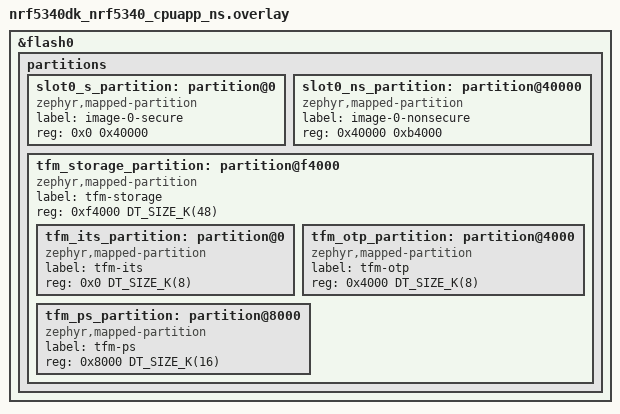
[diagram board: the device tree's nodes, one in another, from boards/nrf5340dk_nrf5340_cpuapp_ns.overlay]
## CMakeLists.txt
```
#
# Copyright (c) 2024 Nordic Semiconductor ASA
#
# SPDX-License-Identifier: LicenseRef-Nordic-5-Clause
#

cmake_minimum_required(VERSION 3.20.0)

find_package(Zephyr REQUIRED HINTS $ENV{ZEPHYR_BASE})
project(decompression_arm_thumb)

target_sources(app PRIVATE src/main.c)

generate_inc_file_for_target(
  app
  ${ZEPHYR_NRFXLIB_MODULE_DIR}/tests/subsys/nrf_compress/decompression/arm_thumb.dat
  ${ZEPHYR_BINARY_DIR}/include/generated/arm_thumb.inc
  )

generate_inc_file_for_target(
  app
  ${ZEPHYR_NRFXLIB_MODULE_DIR}/tests/subsys/nrf_compress/decompression/arm_thumb_compressed.dat
  ${ZEPHYR_BINARY_DIR}/include/generated/arm_thumb_compressed.inc
  )
```

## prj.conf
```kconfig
#
# Copyright (c) 2024 Nordic Semiconductor ASA
#
# SPDX-License-Identifier: LicenseRef-Nordic-5-Clause
#

CONFIG_ZTEST=y
CONFIG_ZTEST_STACK_SIZE=3086
CONFIG_NRF_COMPRESS=y
CONFIG_NRF_COMPRESS_DECOMPRESSION=y
CONFIG_NRF_COMPRESS_ARM_THUMB=y
CONFIG_LOG=y
```

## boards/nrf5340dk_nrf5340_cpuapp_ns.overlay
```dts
/delete-node/ &boot_partition;
/delete-node/ &slot0_partition;
/delete-node/ &slot1_partition;
/delete-node/ &tfm_ps_partition;
/delete-node/ &tfm_its_partition;
/delete-node/ &tfm_otp_partition;
/delete-node/ &storage_partition;

&flash0 {
	partitions {
		slot0_s_partition: partition@0 {
			compatible = "zephyr,mapped-partition";
			label = "image-0-secure";
			reg = <0x0 0x40000>;
		};

		slot0_ns_partition: partition@40000 {
			compatible = "zephyr,mapped-partition";
			label = "image-0-nonsecure";
			reg = <0x40000 0xb4000>;
		};

		tfm_storage_partition: partition@f4000 {
			compatible = "zephyr,mapped-partition";
			label = "tfm-storage";
			reg = <0xf4000 DT_SIZE_K(48)>;
			ranges = <0x0 0xf4000 DT_SIZE_K(48)>;
			#address-cells = <1>;
			#size-cells = <1>;

			tfm_its_partition: partition@0 {
				compatible = "zephyr,mapped-partition";
				label = "tfm-its";
				reg = <0x0 DT_SIZE_K(8)>;
			};

			tfm_otp_partition: partition@4000 {
				compatible = "zephyr,mapped-partition";
				label = "tfm-otp";
				reg = <0x4000 DT_SIZE_K(8)>;
			};

			tfm_ps_partition: partition@8000 {
				compatible = "zephyr,mapped-partition";
				label = "tfm-ps";
				reg = <0x8000 DT_SIZE_K(16)>;
			};
		};
	};
};
```

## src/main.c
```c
/*
 * Copyright (c) 2024 Nordic Semiconductor ASA
 *
 * SPDX-License-Identifier: LicenseRef-Nordic-5-Clause
 */

#include <zephyr/ztest.h>
#include <zephyr/kernel.h>
#include <nrf_compress/implementation.h>

/* Input valid ARM thumb filter compressed data */
static const uint8_t input_compressed[] = {
#include "arm_thumb_compressed.inc"
};

/* Output expected data */
static const uint8_t output_expected[] = {
#include "arm_thumb.inc"
};

#define PLUS_MINUS_OUTPUT_SIZE 2

ZTEST(nrf_compress_decompression, test_valid_implementation)
{
	int rc;
	uint32_t pos = 0;
	uint32_t offset;
	uint8_t *output;
	uint32_t output_size;
	uint32_t total_output_size = 0;
	struct nrf_compress_implementation *implementation = NULL;

	implementation = nrf_compress_implementation_find(NRF_COMPRESS_TYPE_ARM_THUMB);

	zassert_not_equal(implementation, NULL, "Expected implementation to not be NULL");

	rc = implementation->init(NULL, 0);
	zassert_ok(rc, "Expected init to be successful");

	while (pos < sizeof(input_compressed)) {
		uint32_t input_data_size;
		bool last = false;

		input_data_size = implementation->decompress_bytes_needed(NULL);
		zassert_equal(input_data_size, CONFIG_NRF_COMPRESS_CHUNK_SIZE,
			"Expected to need chunk size bytes for LZMA data");

		if ((pos + input_data_size) >= sizeof(input_compressed)) {
			input_data_size = sizeof(input_compressed) - pos;
			last = true;
		}

		rc = implementation->decompress(NULL, &input_compressed[pos], input_data_size,
						last, &offset, &output, &output_size);

		zassert_ok(rc, "Expected data decompress to be successful");
		zassert_mem_equal(output, &output_expected[pos], output_size);

		if (!(output_size == input_data_size || output_size ==
		      (input_data_size + PLUS_MINUS_OUTPUT_SIZE) || output_size ==
		      (input_data_size - PLUS_MINUS_OUTPUT_SIZE))) {
			zassert_ok(1, "Expected data output size is not valid");
		}

		pos += offset;
		total_output_size += output_size;
	}

	zassert_equal(total_output_size, sizeof(output_expected),
		      "Expected data decompress output size to match data input size");

	rc = implementation->deinit(NULL);
	zassert_ok(rc, "Expected deinit to be successful");
}

ZTEST_SUITE(nrf_compress_decompression, NULL, NULL, NULL, NULL, NULL);
```
